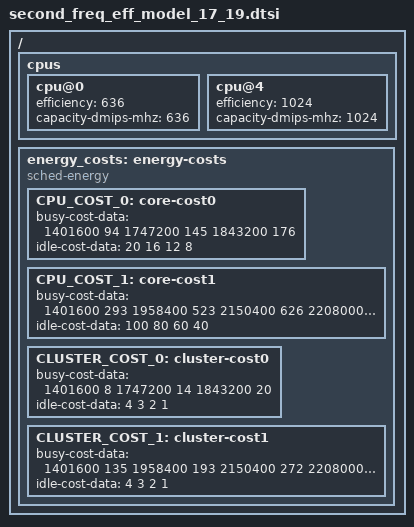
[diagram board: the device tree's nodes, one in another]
/*
 * Auto-generated legacy EAS energy model for incorporation in SoC device tree.
 * Generated by freqbench postprocessing scripts using freqbench results.
 * More info at https://github.com/kdrag0n/freqbench
 */

/ {
	cpus {
		cpu@0 {
			efficiency = <636>;
			capacity-dmips-mhz = <636>;
		};

		cpu@4 {
			efficiency = <1024>;
			capacity-dmips-mhz = <1024>;
		};
	};

	energy_costs: energy-costs {
		compatible = "sched-energy";

		CPU_COST_0: core-cost0 {
			busy-cost-data = <
				 1401600   94
				 1747200  145
				 1843200  176
			>;
			idle-cost-data = <
				20 16 12 8
			>;
		};

		CPU_COST_1: core-cost1 {
			busy-cost-data = <
				 1401600  293
				 1958400  523
				 2150400  626
				 2208000  733
			>;
			idle-cost-data = <
				100 80 60 40
			>;
		};

		CLUSTER_COST_0: cluster-cost0 {
			busy-cost-data = <
				 1401600    8
				 1747200   14
				 1843200   20
			>;
			idle-cost-data = <
				4 3 2 1
			>;
		};

		CLUSTER_COST_1: cluster-cost1 {
			busy-cost-data = <
				 1401600  135
				 1958400  193
				 2150400  272
				 2208000  363
			>;
			idle-cost-data = <
				4 3 2 1
			>;
		};
	};
};
